AUTOSAR XML (schema 00046)
package /Composite_Package
  sender receiver interface SRI_LightStatus
    data LightStatus: type=uint16, init-value=7
  sender receiver interface SRI_LightControl
    data LightActuate: type=uint16
  sensor actuator sw component type LightStatus_SWC1
    provide port Pp_SR_LightStatus: provided-interface=SRI_LightStatus
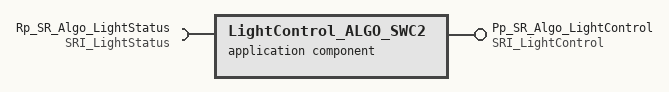
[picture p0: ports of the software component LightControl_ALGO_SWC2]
  application sw component type LightControl_ALGO_SWC2
    require port Rp_SR_Algo_LightStatus: required-interface=SRI_LightStatus
    provide port Pp_SR_Algo_LightControl: provided-interface=SRI_LightControl
  sensor actuator sw component type LightControl_SWC3
    require port Rp_SR_LightActuate: required-interface=SRI_LightControl
  composition sw component type composite1_SWC
    provide port Pp_SR_composite: provided-interface=SRI_LightControl
    component LightStatus_inst: type=LightStatus_SWC1
    component LightControl_Algo_inst: type=LightControl_ALGO_SWC2
    connect LightStatus_inst.Pp_SR_LightStatus -> LightControl_Algo_inst.Rp_SR_Algo_LightStatus
    delegate LightControl_Algo_inst.Pp_SR_Algo_LightControl <-> outer port Pp_SR_composite
  composition sw component type Toplevel_SWC_Composition
    component composite1_SWC_inst: type=composite1_SWC
    component LightControl_SWC3_inst: type=LightControl_SWC3
    connect composite1_SWC_inst.Pp_SR_composite -> LightControl_SWC3_inst.Rp_SR_LightActuate
